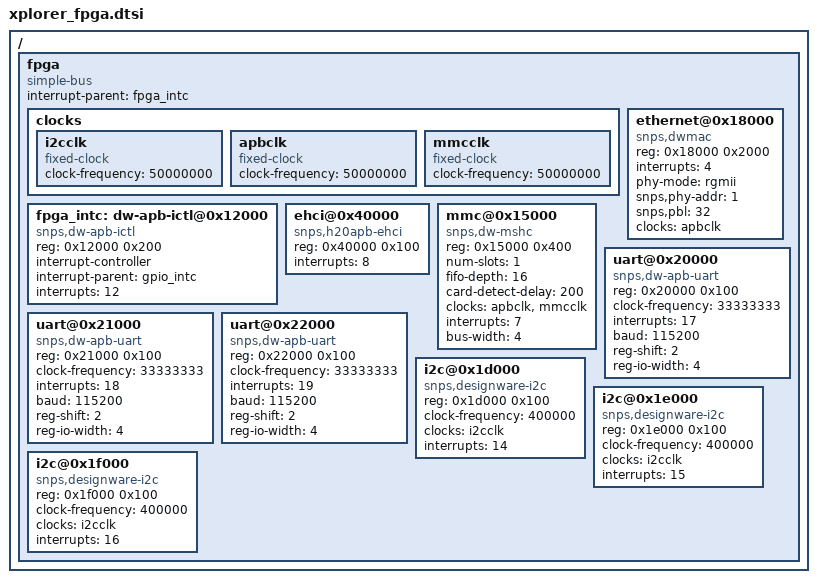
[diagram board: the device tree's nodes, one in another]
/*
 * Copyright (C) 2013 Synopsys, Inc. (www.synopsys.com)
 *
 * This program is free software; you can redistribute it and/or modify
 * it under the terms of the GNU General Public License version 2 as
 * published by the Free Software Foundation.
 */

/ {
	fpga {
		compatible = "simple-bus";
		#address-cells = <1>;
		#size-cells = <1>;
		#interrupt-cells = <1>;
		ranges = <0x00000000 0xe0000000 0x10000000>;
		interrupt-parent = <&fpga_intc>;

		clocks {
			i2cclk: i2cclk {
				compatible = "fixed-clock";
				clock-frequency = <50000000>;
				#clock-cells = <0>;
			};

			apbclk: apbclk {
				compatible = "fixed-clock";
				clock-frequency = <50000000>;
				#clock-cells = <0>;
			};

			mmcclk: mmcclk {
				compatible = "fixed-clock";
				clock-frequency = <50000000>;
				#clock-cells = <0>;
			};
		};

		fpga_intc: dw-apb-ictl@0x12000 {
			#interrupt-cells = <1>;
			compatible = "snps,dw-apb-ictl";
			reg = < 0x12000 0x200 >;
			interrupt-controller;
			interrupt-parent = <&gpio_intc>;
			/* gpio[12] is input for interrupts from FPGA */
			/* first pin is #10, so interrupt idx 2 */
			interrupts = < 12 >;
		};

		ethernet@0x18000 {
			#interrupt-cells = <1>;
			compatible = "snps,dwmac";
			reg = < 0x18000 0x2000 >;
			interrupts = < 4 >;
			interrupt-names = "macirq";
			phy-mode = "rgmii";
			snps,phy-addr = < 1 >;
			snps,pbl = < 32 >;
			clocks = <&apbclk>;
			clock-names = "stmmaceth";
		};

		ehci@0x40000 {
			compatible = "snps,h20apb-ehci";
			reg = < 0x40000 0x100 >;
			interrupts = < 8 >;
		};

		/* ohci@0x60000 {
			compatible = "snps,h20apb-ohci";
			reg = < 0x60000 0x100 >;
			interrupts = < 8 >;
		}; */

		mmc@0x15000 {
			compatible = "snps,dw-mshc";
			reg = < 0x15000 0x400 >;
			num-slots = < 1 >;
			fifo-depth = < 16 >;
			card-detect-delay = < 200 >;
			clocks = <&apbclk>, <&mmcclk>;
			clock-names = "biu", "ciu";
			interrupts = < 7 >;
			bus-width = < 4 >;
		};

		uart@0x20000 {
			compatible = "snps,dw-apb-uart";
			reg = <0x20000 0x100>;
			clock-frequency = <33333333>;
			interrupts = <17>;
			baud = <115200>;
			reg-shift = <2>;
			reg-io-width = <4>;
		};

		uart@0x21000 {
			compatible = "snps,dw-apb-uart";
			reg = <0x21000 0x100>;
			clock-frequency = <33333333>;
			interrupts = <18>;
			baud = <115200>;
			reg-shift = <2>;
			reg-io-width = <4>;
		};

		uart@0x22000 {
			compatible = "snps,dw-apb-uart";
			reg = <0x22000 0x100>;
			clock-frequency = <33333333>;
			interrupts = <19>;
			baud = <115200>;
			reg-shift = <2>;
			reg-io-width = <4>;
		};

		i2c@0x1d000 {
			compatible = "snps,designware-i2c";
			reg = <0x1d000 0x100>;
			clock-frequency = <400000>;
			clocks = <&i2cclk>;
			interrupts = <14>;
		};

		i2c@0x1e000 {
			compatible = "snps,designware-i2c";
			reg = <0x1e000 0x100>;
			clock-frequency = <400000>;
			clocks = <&i2cclk>;
			interrupts = <15>;
		};

		i2c@0x1f000 {
			compatible = "snps,designware-i2c";
			reg = <0x1f000 0x100>;
			clock-frequency = <400000>;
			clocks = <&i2cclk>;
			interrupts = <16>;
		};

	};
};
